# FM33FK5XX register map
File version: 1.0
CPU: Cortex-M33 r1p0, little endian, MPU, FPU, 3 interrupt priority bits
Registers are 32-bit, read-write, reset 0x0 unless marked. A register's access mark holds for its fields unless they carry their own. Offsets are from the block's base; [hi:lo] are bit positions; {n}, {i} and the like mark numbered series; 'fields as' and 'values as' point back to an identical list.

## USB — USB module information
Base 0x50000000
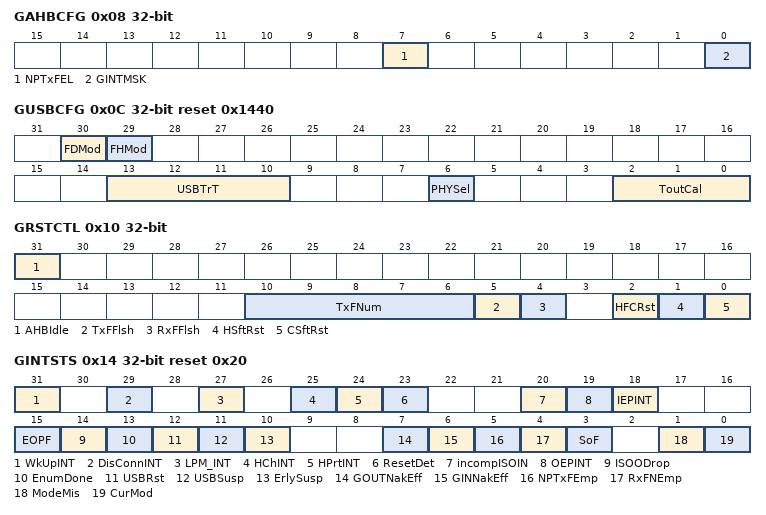
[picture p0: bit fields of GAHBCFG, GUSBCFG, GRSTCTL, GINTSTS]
0x08 GAHBCFG
  [7] NPTxFEL — NPTxFEL field description
  [0] GINTMSK — GINTMSK field description
0x0C GUSBCFG reset 0x1440
  [30] FDMod — FDMod field description
  [29] FHMod — FHMod field description
  [13:10] USBTrT — USBTrT field description
  [6] PHYSel — PHYSel field description
  [2:0] ToutCal — ToutCal field description
0x10 GRSTCTL
  [31] AHBIdle — AHBIdle field description
  [10:6] TxFNum — TxFNum field description
  [5] TxFFlsh — TxFFlsh field description
  [4] RxFFlsh — RxFFlsh field description
  [2] HFCRst — HFCRst field description
  [1] HSftRst — HSftRst field description
  [0] CSftRst — CSftRst field description
0x14 GINTSTS access per field reset 0x20
  [31] WkUpINT rw — WkUpINT field description
  [29] DisConnINT rw — DisConnINT field description
  [27] LPM_INT rw — LPM_INT field description
  [25] HChINT ro — HChINT field description
  [24] HPrtINT ro — HPrtINT field description
  [23] ResetDet rw — ResetDet field description
  [20] incompISOIN rw — incompISOIN field description
  [19] OEPINT ro — OEPINT field description
  [18] IEPINT ro — IEPINT field description
  [15] EOPF rw — EOPF field description
  [14] ISOODrop rw — ISOODrop field description
  [13] EnumDone rw — EnumDone field description
  [12] USBRst rw — USBRst field description
  [11] USBSusp rw — USBSusp field description
  [10] ErlySusp rw — ErlySusp field description
  [7] GOUTNakEff ro — GOUTNakEff field description
  [6] GINNakEff ro — GINNakEff field description
  [5] NPTxFEmp ro — NPTxFEmp field description
  [4] RxFNEmp ro — RxFNEmp field description
  [3] SoF rw — SoF field description
  [1] ModeMis rw — ModeMis field description
  [0] CurMod ro — CurMod field description
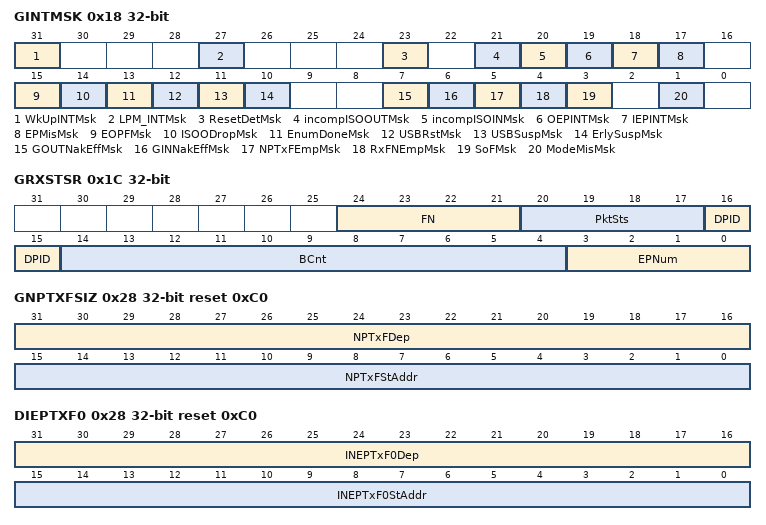
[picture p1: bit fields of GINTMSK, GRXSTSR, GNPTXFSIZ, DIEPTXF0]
0x18 GINTMSK
  [31] WkUpINTMsk — WkUpINTMsk field description
  [27] LPM_INTMsk — LPM_INTMsk field description
  [23] ResetDetMsk — ResetDetMsk field description
  [21] incompISOOUTMsk — incompISOOUTMsk field description
  [20] incompISOINMsk — incompISOINMsk field description
  [19] OEPINTMsk — OEPINTMsk field description
  [18] IEPINTMsk — IEPINTMsk field description
  [17] EPMisMsk — EPMisMsk field description
  [15] EOPFMsk — EOPFMsk field description
  [14] ISOODropMsk — ISOODropMsk field description
  [13] EnumDoneMsk — EnumDoneMsk field description
  [12] USBRstMsk — USBRstMsk field description
  [11] USBSuspMsk — USBSuspMsk field description
  [10] ErlySuspMsk — ErlySuspMsk field description
  [7] GOUTNakEffMsk — GOUTNakEffMsk field description
  [6] GINNakEffMsk — GINNakEffMsk field description
  [5] NPTxFEmpMsk — NPTxFEmpMsk field description
  [4] RxFNEmpMsk — RxFNEmpMsk field description
  [3] SoFMsk — SoFMsk field description
  [1] ModeMisMsk — ModeMisMsk field description
0x1C GRXSTSR ro
  [24:21] FN — FN field description
  [20:17] PktSts — PktSts field description
  [16:15] DPID — DPID field description
  [14:4] BCnt — BCnt field description
  [3:0] EPNum — EPNum field description
0x24 GRXFSIZ ro reset 0x80
  [15:0] RxFDep — RxFDep field description
0x28 GNPTXFSIZ ro reset 0xC0
  [31:16] NPTxFDep — NPTxFDep field description
  [15:0] NPTxFStAddr — NPTxFStAddr field description
0x28 DIEPTXF0 ro reset 0xC0 (alternate view of GNPTXFSIZ)
  [31:16] INEPTxF0Dep — INEPTxF0Dep field description
  [15:0] INEPTxF0StAddr — INEPTxF0StAddr field description
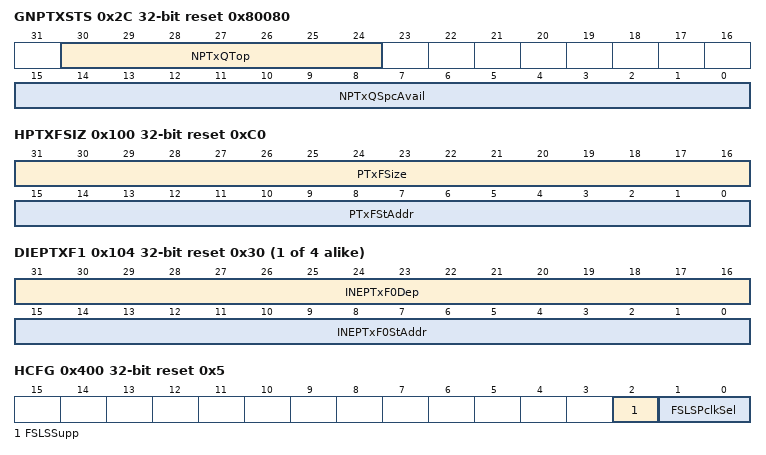
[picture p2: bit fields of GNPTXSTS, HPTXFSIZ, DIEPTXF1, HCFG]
0x2C GNPTXSTS ro reset 0x80080
  [30:24] NPTxQTop — NPTxQTop field description
  [15:0] NPTxQSpcAvail — NPTxQSpcAvail field description
0x100 HPTXFSIZ reset 0xC0
  [31:16] PTxFSize — PTxFSize field description
  [15:0] PTxFStAddr — PTxFStAddr field description
{0x100+4i} DIEPTXF{i} ro reset 0x30 (i=1..4)
  fields as DIEPTXF0
0x400 HCFG reset 0x5
  [2] FSLSSupp — FSLSSupp field description
  [1:0] FSLSPclkSel — FSLSPclkSel field description
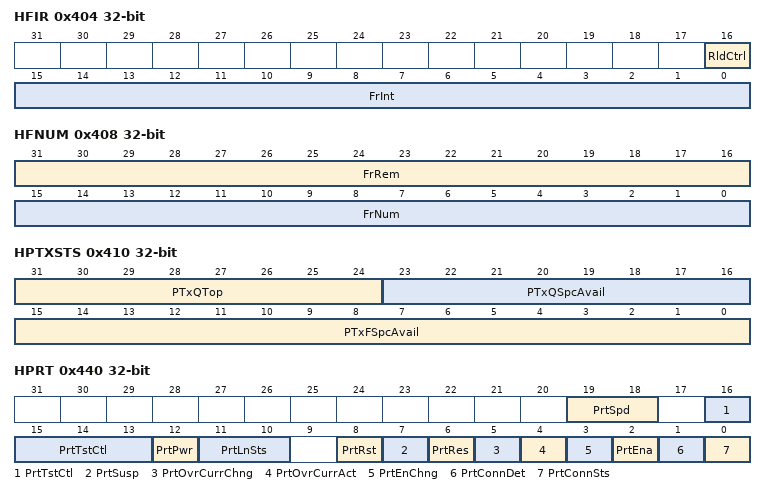
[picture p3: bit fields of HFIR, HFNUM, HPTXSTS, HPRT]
0x404 HFIR
  [16] RldCtrl — RldCtrl field description
  [15:0] FrInt — FrInt field description
0x408 HFNUM ro
  [31:16] FrRem — FrRem field description
  [15:0] FrNum — FrNum field description
0x410 HPTXSTS access per field
  [31:24] PTxQTop ro — PTxQTop field description
  [23:16] PTxQSpcAvail ro — PTxQSpcAvail field description
  [15:0] PTxFSpcAvail rw — PTxFSpcAvail field description
0x414 HAINT ro
  [4:0] HAINT — HAINT field description
0x418 HAINTMSK ro
  [4:0] HAINTMSK — HAINTMSK field description
0x440 HPRT access per field
  [19:18] PrtSpd ro — PrtSpd field description
  [16:13] PrtTstCtl rw — PrtTstCtl field description
  [12] PrtPwr rw — PrtPwr field description
  [11:10] PrtLnSts rw — PrtLnSts field description
  [8] PrtRst rw — PrtRst field description
  [7] PrtSusp rw — PrtSusp field description
  [6] PrtRes rw — PrtRes field description
  [5] PrtOvrCurrChng rw — PrtOvrCurrChng field description
  [4] PrtOvrCurrAct ro — PrtOvrCurrAct field description
  [3] PrtEnChng rw — PrtEnChng field description
  [2] PrtEna rw — PrtEna field description
  [1] PrtConnDet rw — PrtConnDet field description
  [0] PrtConnSts ro — PrtConnSts field description
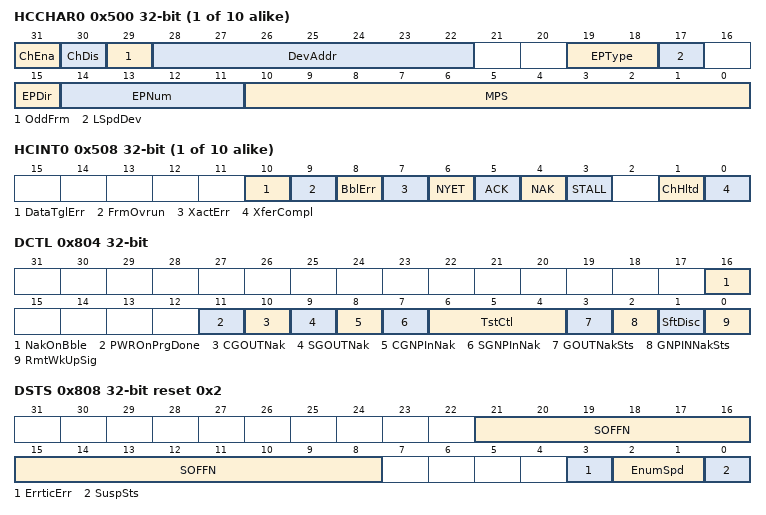
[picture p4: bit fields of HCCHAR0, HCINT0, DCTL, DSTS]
{0x500+0x20*i} HCCHAR{i} (i=0..9)
  [31] ChEna — ChEna field description
  [30] ChDis — ChDis field description
  [29] OddFrm — OddFrm field description
  [28:22] DevAddr — DevAddr field description
  [19:18] EPType — EPType field description
  [17] LSpdDev — LSpdDev field description
  [15] EPDir — EPDir field description
  [14:11] EPNum — EPNum field description
  [10:0] MPS — MPS field description
{0x508+0x20*i} HCINT{i} (i=0..9)
  [10] DataTglErr — DataTglErr field description
  [9] FrmOvrun — FrmOvrun field description
  [8] BblErr — BblErr field description
  [7] XactErr — XactErr field description
  [6] NYET — NYET field description
  [5] ACK — ACK field description
  [4] NAK — NAK field description
  [3] STALL — STALL field description
  [1] ChHltd — ChHltd field description
  [0] XferCompl — XferCompl field description
0x804 DCTL access per field
  [16] NakOnBble rw — NakOnBble field description
  [11] PWROnPrgDone rw — PWROnPrgDone field description
  [10] CGOUTNak rw — CGOUTNak field description
  [9] SGOUTNak rw — SGOUTNak field description
  [8] CGNPInNak rw — CGNPInNak field description
  [7] SGNPInNak rw — SGNPInNak field description
  [6:4] TstCtl rw — TstCtl field description
  [3] GOUTNakSts ro — GOUTNakSts field description
  [2] GNPINNakSts ro — GNPINNakSts field description
  [1] SftDisc rw — SftDisc field description
  [0] RmtWkUpSig rw — RmtWkUpSig field description
0x808 DSTS ro reset 0x2
  [21:8] SOFFN — SOFFN field description
  [3] ErrticErr — ErrticErr field description
  [2:1] EnumSpd — EnumSpd field description
  [0] SuspSts — SuspSts field description
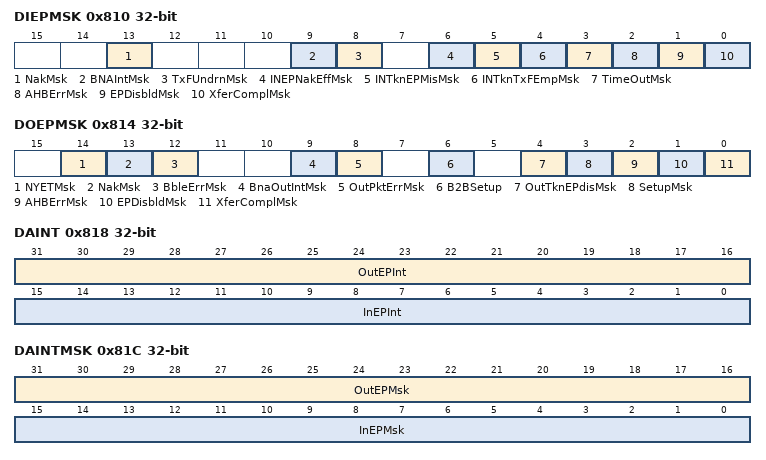
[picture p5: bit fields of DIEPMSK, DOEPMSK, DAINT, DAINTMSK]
0x810 DIEPMSK
  [13] NakMsk — NakMsk field description
  [9] BNAIntMsk — BNAIntMsk field description
  [8] TxFUndrnMsk — TxFUndrnMsk field description
  [6] INEPNakEffMsk — INEPNakEffMsk field description
  [5] INTknEPMisMsk — INTknEPMisMsk field description
  [4] INTknTxFEmpMsk — INTknTxFEmpMsk field description
  [3] TimeOutMsk — TimeOutMsk field description
  [2] AHBErrMsk — AHBErrMsk field description
  [1] EPDisbldMsk — EPDisbldMsk field description
  [0] XferComplMsk — XferComplMsk field description
0x814 DOEPMSK
  [14] NYETMsk — NYETMsk field description
  [13] NakMsk — NakMsk field description
  [12] BbleErrMsk — BbleErrMsk field description
  [9] BnaOutIntMsk — BnaOutIntMsk field description
  [8] OutPktErrMsk — OutPktErrMsk field description
  [6] B2BSetup — B2BSetup field description
  [4] OutTknEPdisMsk — OutTknEPdisMsk field description
  [3] SetupMsk — SetupMsk field description
  [2] AHBErrMsk — AHBErrMsk field description
  [1] EPDisbldMsk — EPDisbldMsk field description
  [0] XferComplMsk — XferComplMsk field description
0x818 DAINT ro
  [31:16] OutEPInt — OutEPInt field description
  [15:0] InEPInt — InEPInt field description
0x81C DAINTMSK
  [31:16] OutEPMsk — OutEPMsk field description
  [15:0] InEPMsk — InEPMsk field description
0x834 DIEPEMPMSK
  [2:0] InEpTxfEmpMsk — InEpTxfEmpMsk field description
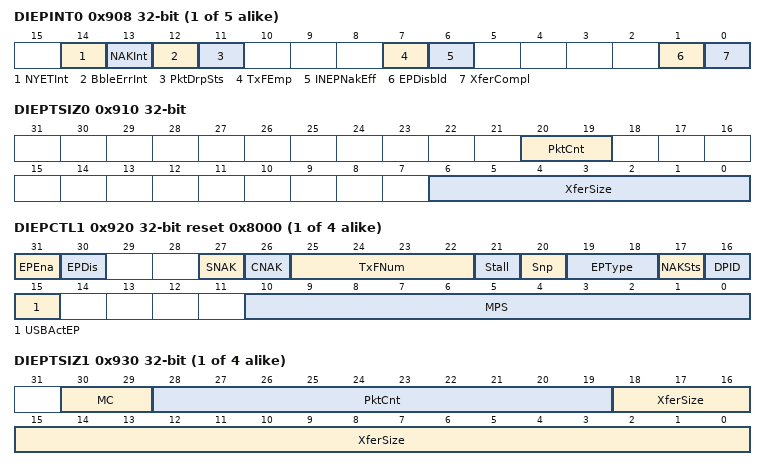
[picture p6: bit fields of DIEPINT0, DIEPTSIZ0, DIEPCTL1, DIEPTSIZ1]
{0x908+0x20*i} DIEPINT{i} access per field (i=0..4)
  [14] NYETInt rw — NYETInt field description
  [13] NAKInt rw — NAKInt field description
  [12] BbleErrInt rw — BbleErrInt field description
  [11] PktDrpSts rw — PktDrpSts field description
  [7] TxFEmp ro — TxFEmp field description
  [6] INEPNakEff rw — INEPNakEff field description
  [1] EPDisbld rw — EPDisbld field description
  [0] XferCompl rw — XferCompl field description
0x910 DIEPTSIZ0
  [20:19] PktCnt — PktCnt field description
  [6:0] XferSize — XferSize field description
{0x918+0x20*i} DTXFSTS{i} reset 0x10 (i=0..4)
  [15:0] INEPTxFSpcAvail — INEPTxFSpcAvail field description
{0x900+0x20*i} DIEPCTL{i} access per field reset 0x8000 (i=1..4)
  [31] EPEna rw — EPEna field description
  [30] EPDis rw — EPDis field description
  [27] SNAK rw — SNAK field description
  [26] CNAK rw — CNAK field description
  [25:22] TxFNum rw — TxFNum field description
  [21] Stall rw — Stall field description
  [20] Snp rw — Snp field description
  [19:18] EPType rw — EPType field description
  [17] NAKSts ro — NAKSts field description
  [16] DPID ro — DPID field description
  [15] USBActEP ro — USBActEP field description
  [10:0] MPS rw — MPS field description
{0x910+0x20*i} DIEPTSIZ{i} (i=1..4)
  [30:29] MC — MC field description
  [28:19] PktCnt — PktCnt field description
  [18:0] XferSize — XferSize field description
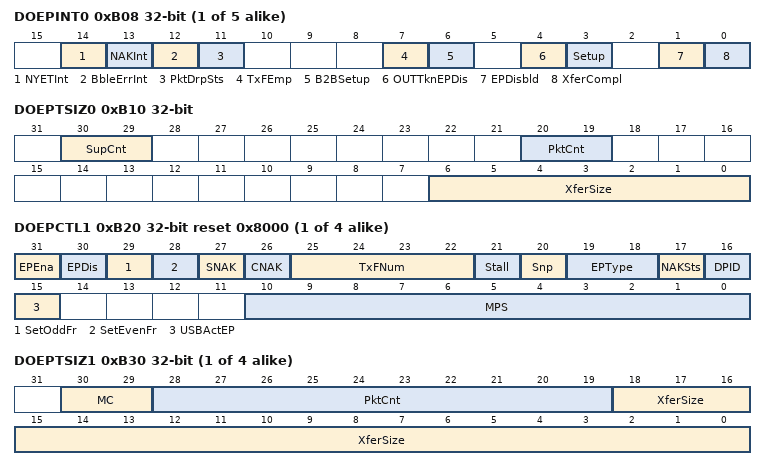
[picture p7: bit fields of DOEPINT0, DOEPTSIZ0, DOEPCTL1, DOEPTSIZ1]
{0xB08+0x20*i} DOEPINT{i} access per field (i=0..4)
  [14] NYETInt rw — NYETInt field description
  [13] NAKInt rw — NAKInt field description
  [12] BbleErrInt rw — BbleErrInt field description
  [11] PktDrpSts rw — PktDrpSts field description
  [7] TxFEmp ro — TxFEmp field description
  [6] B2BSetup rw — B2BSetup field description
  [4] OUTTknEPDis rw — OUTTknEPDis field description
  [3] Setup rw — Setup field description
  [1] EPDisbld rw — EPDisbld field description
  [0] XferCompl rw — XferCompl field description
0xB10 DOEPTSIZ0
  [30:29] SupCnt — SupCnt field description
  [20:19] PktCnt — PktCnt field description
  [6:0] XferSize — XferSize field description
{0xB00+0x20*i} DOEPCTL{i} access per field reset 0x8000 (i=1..4)
  [31] EPEna rw — EPEna field description
  [30] EPDis rw — EPDis field description
  [29] SetOddFr rw — SetOddFr field description
  [28] SetEvenFr rw — SetEvenFr field description
  [27] SNAK rw — SNAK field description
  [26] CNAK rw — CNAK field description
  [25:22] TxFNum rw — TxFNum field description
  [21] Stall rw — Stall field description
  [20] Snp rw — Snp field description
  [19:18] EPType rw — EPType field description
  [17] NAKSts ro — NAKSts field description
  [16] DPID ro — DPID field description
  [15] USBActEP ro — USBActEP field description
  [10:0] MPS rw — MPS field description
{0xB10+0x20*i} DOEPTSIZ{i} (i=1..4)
  fields as DIEPTSIZ1
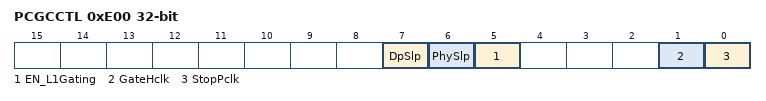
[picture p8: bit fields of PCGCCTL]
0xE00 PCGCCTL access per field
  [7] DpSlp ro — DpSlp field description
  [6] PhySlp ro — PhySlp field description
  [5] EN_L1Gating rw — EN_L1Gating field description
  [1] GateHclk rw — GateHclk field description
  [0] StopPclk rw — StopPclk field description
